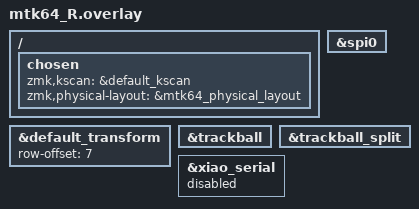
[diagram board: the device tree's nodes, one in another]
#include "mtk64.dtsi"
#include "mtk64_trackball.dtsi"

/ {
    chosen {
        zmk,kscan = &default_kscan;
        zmk,physical-layout = &mtk64_physical_layout;
    };
};

&default_transform {
    row-offset = <7>;
};

/*
&kscan0 {
    gpios
        = <&xiao_d 1 GPIO_ACTIVE_HIGH> 
        , <&xiao_d 2 GPIO_ACTIVE_HIGH> 
        , <&xiao_d 3 GPIO_ACTIVE_HIGH> 
        , <&xiao_d 6 GPIO_ACTIVE_HIGH>
        , <&xiao_d 7 GPIO_ACTIVE_HIGH> 
        , <&xiao_d 8 GPIO_ACTIVE_HIGH> 
        , <&xiao_d 9 GPIO_ACTIVE_HIGH> 	
    ;
};
*/

&spi0 {
    status = "okay";
};

&trackball { 
    status = "okay";
};

&trackball_split { 
    status = "okay";
};

&xiao_serial { status = "disabled"; };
